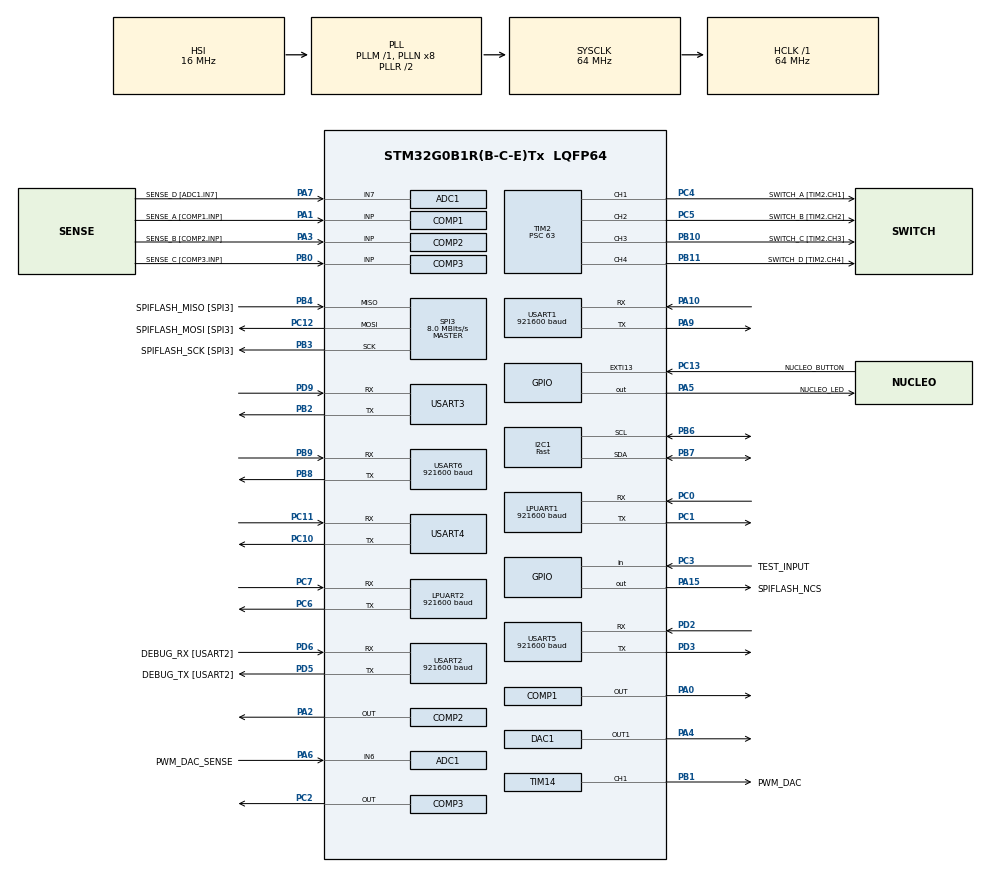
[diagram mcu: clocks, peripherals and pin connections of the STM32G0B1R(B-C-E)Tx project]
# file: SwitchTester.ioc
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ADC1.ContinuousConvMode=DISABLE
ADC1.DMAContinuousRequests=ENABLE
ADC1.EOCSelection=ADC_EOC_SEQ_CONV
ADC1.EnableAnalogWatchDog1=false
ADC1.NbrOfConversion=1
ADC1.NbrOfConversionFlag=0
ADC1.OversamplingMode=ENABLE
ADC1.Ratio=ADC_OVERSAMPLING_RATIO_4
ADC1.SamplingTimeCommon1=ADC_SAMPLETIME_12CYCLES_5
ADC1.SelectedChannel=ADC_CHANNEL_6|ADC_CHANNEL_7|ADC_CHANNEL_VREFINT|ADC_CHANNEL_VBAT
ADC1.Sequencer=NOT_FULLY_CONFIGURABLE
ADC1.master=1
COMP1.Hysteresis=COMP_HYSTERESIS_LOW
COMP1.TriggerMode=COMP_TRIGGERMODE_IT_RISING_FALLING
COMP2.Hysteresis=COMP_HYSTERESIS_LOW
COMP2.TriggerMode=COMP_TRIGGERMODE_IT_RISING_FALLING
COMP3.Hysteresis=COMP_HYSTERESIS_LOW
COMP3.TriggerMode=COMP_TRIGGERMODE_IT_RISING_FALLING
DAC1.DAC_Channel-DAC_OUT1_ExtAndInt=DAC_CHANNEL_1
DAC1.DAC_Channel-DAC_OUT2_Int=DAC_CHANNEL_2
Dma.ADC1.2.Direction=DMA_PERIPH_TO_MEMORY
Dma.ADC1.2.EventEnable=DISABLE
Dma.ADC1.2.Instance=DMA1_Channel3
Dma.ADC1.2.MemDataAlignment=DMA_MDATAALIGN_HALFWORD
Dma.ADC1.2.MemInc=DMA_MINC_ENABLE
Dma.ADC1.2.Mode=DMA_CIRCULAR
Dma.ADC1.2.PeriphDataAlignment=DMA_PDATAALIGN_HALFWORD
Dma.ADC1.2.PeriphInc=DMA_PINC_DISABLE
Dma.ADC1.2.Polarity=HAL_DMAMUX_REQ_GEN_RISING
Dma.ADC1.2.Priority=DMA_PRIORITY_LOW
Dma.ADC1.2.RequestNumber=1
Dma.ADC1.2.SignalID=NONE
Dma.ADC1.2.SyncEnable=DISABLE
Dma.ADC1.2.SyncPolarity=HAL_DMAMUX_SYNC_NO_EVENT
Dma.ADC1.2.SyncRequestNumber=1
Dma.ADC1.2.SyncSignalID=NONE
Dma.Request0=SPI3_RX
Dma.Request1=SPI3_TX
Dma.Request2=ADC1
Dma.SPI3_RX.0.Direction=DMA_PERIPH_TO_MEMORY
Dma.SPI3_RX.0.EventEnable=DISABLE
Dma.SPI3_RX.0.Instance=DMA1_Channel1
Dma.SPI3_RX.0.MemDataAlignment=DMA_MDATAALIGN_BYTE
Dma.SPI3_RX.0.MemInc=DMA_MINC_ENABLE
Dma.SPI3_RX.0.Mode=DMA_NORMAL
Dma.SPI3_RX.0.PeriphDataAlignment=DMA_PDATAALIGN_BYTE
Dma.SPI3_RX.0.PeriphInc=DMA_PINC_DISABLE
Dma.SPI3_RX.0.Polarity=HAL_DMAMUX_REQ_GEN_RISING
Dma.SPI3_RX.0.Priority=DMA_PRIORITY_LOW
Dma.SPI3_RX.0.RequestNumber=1
Dma.SPI3_RX.0.SignalID=NONE
Dma.SPI3_RX.0.SyncEnable=DISABLE
Dma.SPI3_RX.0.SyncPolarity=HAL_DMAMUX_SYNC_NO_EVENT
Dma.SPI3_RX.0.SyncRequestNumber=1
Dma.SPI3_RX.0.SyncSignalID=NONE
Dma.SPI3_TX.1.Direction=DMA_MEMORY_TO_PERIPH
Dma.SPI3_TX.1.EventEnable=DISABLE
Dma.SPI3_TX.1.Instance=DMA1_Channel2
Dma.SPI3_TX.1.MemDataAlignment=DMA_MDATAALIGN_BYTE
Dma.SPI3_TX.1.MemInc=DMA_MINC_ENABLE
Dma.SPI3_TX.1.Mode=DMA_NORMAL
Dma.SPI3_TX.1.PeriphDataAlignment=DMA_PDATAALIGN_BYTE
Dma.SPI3_TX.1.PeriphInc=DMA_PINC_DISABLE
Dma.SPI3_TX.1.Polarity=HAL_DMAMUX_REQ_GEN_RISING
Dma.SPI3_TX.1.Priority=DMA_PRIORITY_LOW
Dma.SPI3_TX.1.RequestNumber=1
Dma.SPI3_TX.1.SignalID=NONE
Dma.SPI3_TX.1.SyncEnable=DISABLE
Dma.SPI3_TX.1.SyncPolarity=HAL_DMAMUX_SYNC_NO_EVENT
Dma.SPI3_TX.1.SyncRequestNumber=1
Dma.SPI3_TX.1.SyncSignalID=NONE
I2C1.I2C_Speed_Mode=I2C_Fast
I2C1.Timing=0x00C12166
LPUART1.BaudRate=921600
LPUART1.FifoMode=UART_FIFOMODE_ENABLE
LPUART1.RXFIFOThreshold=UART_RXFIFO_THRESHOLD_1_2
LPUART1.TXFIFOThreshold=UART_TXFIFO_THRESHOLD_1_2
LPUART1.WordLength=UART_WORDLENGTH_8B
LPUART2.BaudRate=921600
LPUART2.FifoMode=UART_FIFOMODE_ENABLE
LPUART2.RXFIFOThreshold=UART_RXFIFO_THRESHOLD_1_2
LPUART2.TXFIFOThreshold=UART_TXFIFO_THRESHOLD_1_2
LPUART2.WordLength=UART_WORDLENGTH_8B
Mcu.Family=STM32G0
Mcu.Name=STM32G0B1R(B-C-E)Tx
Mcu.Package=LQFP64
NVIC.ADC1_COMP_IRQn=true\:1\:0\:true\:false\:true\:false\:true\:true
NVIC.DMA1_Channel1_IRQn=true\:0\:0\:false\:false\:true\:false\:true\:true
NVIC.DMA1_Channel2_3_IRQn=true\:0\:0\:false\:false\:true\:false\:true\:true
NVIC.EXTI4_15_IRQn=true\:3\:0\:true\:false\:true\:true\:true\:true
NVIC.RTC_TAMP_IRQn=true\:3\:0\:true\:false\:true\:true\:true\:true
NVIC.TIM17_FDCAN_IT1_IRQn=true\:3\:0\:true\:false\:true\:true\:true\:true
NVIC.TIM2_IRQn=true\:0\:0\:false\:false\:true\:true\:true\:true
NVIC.USART1_IRQn=true\:2\:0\:true\:false\:true\:true\:true\:true
NVIC.USART2_LPUART2_IRQn=true\:2\:0\:true\:false\:true\:true\:true\:true
NVIC.USART3_4_5_6_LPUART1_IRQn=true\:2\:0\:true\:false\:true\:true\:true\:true
PA0.Mode=ExternalOutput
PA0.Signal=COMP1_OUT
PA1.GPIO_Label=SENSE_A [COMP1.INP]
PA1.Mode=INP
PA1.Signal=COMP1_INP
PA10.Mode=Asynchronous
PA10.Signal=USART1_RX
PA13.GPIO_Label=SWDIO
PA13.Mode=Serial_Wire
PA13.Signal=SYS_SWDIO
PA14-BOOT0.GPIO_Label=SWCLK
PA14-BOOT0.Mode=Serial_Wire
PA14-BOOT0.Signal=SYS_SWCLK
PA15.GPIO_Label=SPIFLASH_NCS
PA15.PinState=GPIO_PIN_SET
PA15.Signal=GPIO_Output
PA2.Mode=ExternalOutput
PA2.Signal=COMP2_OUT
PA3.GPIO_Label=SENSE_B [COMP2.INP]
PA3.Mode=INP
PA3.Signal=COMP2_INP
PA4.Signal=COMP_DAC11_group
PA5.GPIO_Label=NUCLEO_LED
PA5.Signal=GPIO_Output
PA6.GPIO_Label=PWM_DAC_SENSE
PA6.Mode=IN6
PA6.Signal=ADC1_IN6
PA7.GPIO_Label=SENSE_D [ADC1.IN7]
PA7.Mode=IN7
PA7.Signal=ADC1_IN7
PA9.Mode=Asynchronous
PA9.Signal=USART1_TX
PB0.GPIO_Label=SENSE_C [COMP3.INP]
PB0.Mode=INP
PB0.Signal=COMP3_INP
PB1.GPIO_Label=PWM_DAC
PB1.Signal=S_TIM14_CH1
PB10.GPIO_Label=SWITCH_C [TIM2.CH3]
PB10.Signal=S_TIM2_CH3
PB11.GPIO_Label=SWITCH_D [TIM2.CH4]
PB11.Signal=S_TIM2_CH4
PB2.Mode=Asynchronous
PB2.Signal=USART3_TX
PB3.GPIO_Label=SPIFLASH_SCK [SPI3]
PB3.Mode=Full_Duplex_Master
PB3.Signal=SPI3_SCK
PB4.GPIO_Label=SPIFLASH_MISO [SPI3]
PB4.Mode=Full_Duplex_Master
PB4.Signal=SPI3_MISO
PB6.Mode=I2C
PB6.Signal=I2C1_SCL
PB7.Mode=I2C
PB7.Signal=I2C1_SDA
PB8.Mode=Asynchronous
PB8.Signal=USART6_TX
PB9.Mode=Asynchronous
PB9.Signal=USART6_RX
PC0.Mode=Asynchronous
PC0.Signal=LPUART1_RX
PC1.Mode=Asynchronous
PC1.Signal=LPUART1_TX
PC10.Mode=Asynchronous
PC10.Signal=USART4_TX
PC11.Mode=Asynchronous
PC11.Signal=USART4_RX
PC12.GPIO_Label=SPIFLASH_MOSI [SPI3]
PC12.Mode=Full_Duplex_Master
PC12.Signal=SPI3_MOSI
PC13.GPIO_Label=NUCLEO_BUTTON
PC13.GPIO_ModeDefaultEXTI=GPIO_MODE_IT_FALLING
PC13.Signal=GPXTI13
PC14-OSC32_IN\ (PC14).GPIO_Label=RTC_OSC32_IN
PC14-OSC32_IN\ (PC14).Mode=LSE-External-Oscillator
PC14-OSC32_IN\ (PC14).Signal=RCC_OSC32_IN
PC15-OSC32_OUT\ (PC15).GPIO_Label=RTC_OSC32_OUT
PC15-OSC32_OUT\ (PC15).Mode=LSE-External-Oscillator
PC15-OSC32_OUT\ (PC15).Signal=RCC_OSC32_OUT
PC2.Mode=ExternalOutput
PC2.Signal=COMP3_OUT
PC3.GPIO_Label=TEST_INPUT
PC3.GPIO_PuPd=GPIO_PULLUP
PC3.Signal=GPIO_Input
PC4.GPIO_Label=SWITCH_A [TIM2.CH1]
PC4.Signal=S_TIM2_CH1_ETR
PC5.GPIO_Label=SWITCH_B [TIM2.CH2]
PC5.Signal=S_TIM2_CH2
PC6.Mode=Asynchronous
PC6.Signal=LPUART2_TX
PC7.Mode=Asynchronous
PC7.Signal=LPUART2_RX
PD2.Mode=Asynchronous
PD2.Signal=USART5_RX
PD3.Mode=Asynchronous
PD3.Signal=USART5_TX
PD5.GPIO_Label=DEBUG_TX [USART2]
PD5.Mode=Asynchronous
PD5.Signal=USART2_TX
PD6.GPIO_Label=DEBUG_RX [USART2]
PD6.Mode=Asynchronous
PD6.Signal=USART2_RX
PD9.Mode=Asynchronous
PD9.Signal=USART3_RX
ProjectManager.HeapSize=0x400
ProjectManager.StackSize=0x400
ProjectManager.TargetToolchain=STM32CubeIDE
RCC.ADCFreq_Value=64000000
RCC.AHBFreq_Value=64000000
RCC.CortexFreq_Value=64000000
RCC.EXTERNAL_CLOCK_VALUE=12288000
RCC.HCLKFreq_Value=64000000
RCC.HSE_VALUE=8000000
RCC.HSI48_VALUE=48000000
RCC.HSI_VALUE=16000000
RCC.SYSCLKFreq_VALUE=64000000
RCC.SYSCLKSource=RCC_SYSCLKSOURCE_PLLCLK
RCC.USBFreq_Value=48000000
RCC.VCOOutputFreq_Value=128000000
RTC.SynchPrediv=249
SH.COMP_DAC11_group.0=DAC1_OUT1,DAC_OUT1_ExtAndInt
SH.S_TIM14_CH1.0=TIM14_CH1,PWM Generation1 CH1
SH.S_TIM2_CH1_ETR.0=TIM2_CH1,Output Compare1 CH1
SH.S_TIM2_CH2.0=TIM2_CH2,Output Compare2 CH2
SH.S_TIM2_CH3.0=TIM2_CH3,Output Compare3 CH3
SH.S_TIM2_CH4.0=TIM2_CH4,Output Compare4 CH4
SPI3.BaudRatePrescaler=SPI_BAUDRATEPRESCALER_8
SPI3.CalculateBaudRate=8.0 MBits/s
SPI3.DataSize=SPI_DATASIZE_8BIT
SPI3.Direction=SPI_DIRECTION_2LINES
SPI3.Mode=SPI_MODE_MASTER
SPI3.VirtualType=VM_MASTER
TIM1.Channel-Input_Capture1_from_TI1_REMAP_TIM1=TIM_CHANNEL_1
TIM1.Channel-Input_Capture2_from_TI2_Remap_TIM1=TIM_CHANNEL_2
TIM1.Channel-Input_Capture3_from_TI3_Remap_TIM1=TIM_CHANNEL_3
TIM1.ICPolarity_CH1=TIM_INPUTCHANNELPOLARITY_BOTHEDGE
TIM1.ICPolarity_CH2-Input_Capture2_from_TI2_Remap_TIM1=TIM_INPUTCHANNELPOLARITY_BOTHEDGE
TIM1.ICPolarity_CH2-Input_Capture3_from_TI3_Remap_TIM1=TIM_INPUTCHANNELPOLARITY_BOTHEDGE
TIM14.Channel=TIM_CHANNEL_1
TIM14.Period=1023
TIM14.Prescaler=0
TIM17.Period=999
TIM17.Prescaler=63
TIM2.Channel-Output\ Compare1\ CH1=TIM_CHANNEL_1
TIM2.Channel-Output\ Compare2\ CH2=TIM_CHANNEL_2
TIM2.Channel-Output\ Compare3\ CH3=TIM_CHANNEL_3
TIM2.Channel-Output\ Compare4\ CH4=TIM_CHANNEL_4
TIM2.OCMode_1=TIM_OCMODE_FORCED_INACTIVE
TIM2.OCMode_2=TIM_OCMODE_FORCED_INACTIVE
TIM2.OCMode_3=TIM_OCMODE_FORCED_INACTIVE
TIM2.OCMode_4=TIM_OCMODE_FORCED_INACTIVE
TIM2.Prescaler=63
TIM6.Period=99
TIM6.Prescaler=63
TIM7.Prescaler=63
USART1.BaudRate=921600
USART1.FIFOMode=FIFOMODE_ENABLE
USART1.RXFIFOThreshold=RXFIFO_THRESHOLD_HALFFULL
USART1.TXFIFOThreshold=TXFIFO_THRESHOLD_HALFFULL
USART1.VirtualMode-Asynchronous=VM_ASYNC
USART2.BaudRate=921600
USART2.FIFOMode=FIFOMODE_ENABLE
USART2.RXFIFOThreshold=RXFIFO_THRESHOLD_1QUARTERFULL
USART2.TXFIFOThreshold=TXFIFO_THRESHOLD_1QUARTERFULL
USART2.VirtualMode-Asynchronous=VM_ASYNC
USART3.FIFOMode=FIFOMODE_ENABLE
USART3.RXFIFOThreshold=RXFIFO_THRESHOLD_HALFFULL
USART3.TXFIFOThreshold=TXFIFO_THRESHOLD_HALFFULL
USART3.VirtualMode-Asynchronous=VM_ASYNC
USART4.VirtualMode-Asynchronous=VM_ASYNC
USART5.BaudRate=921600
USART5.VirtualMode-Asynchronous=VM_ASYNC
USART6.BaudRate=921600
USART6.VirtualMode-Asynchronous=VM_ASYNC
VP_ADC1_Vbat_Input.Mode=IN-Vbat
VP_ADC1_Vref_Input.Mode=IN-Vrefint
VP_COMP1_VS_DACOUT1.Mode=INM_DACOUT1
VP_COMP2_VS_DACOUT2.Mode=INM_DACOUT2
VP_COMP3_VS_DACOUT2.Mode=INM_DACOUT2
VP_CRC_VS_CRC.Mode=CRC_Activate
VP_DAC1_VS_DACI2.Mode=DAC_OUT2_Int
VP_RTC_VS_RTC_Activate.Mode=RTC_Enabled
VP_RTC_VS_RTC_WakeUp_intern.Mode=WakeUp
VP_SYS_VS_DBSignals.Mode=DisableDeadBatterySignals
VP_TIM14_VS_ClockSourceINT.Mode=Enable_Timer
VP_TIM17_VS_ClockSourceINT.Mode=Enable_Timer
VP_TIM1_VS_ClockSourceINT.Mode=Internal
VP_TIM1_VS_NoInput1.Mode=Input_Capture1_from_TI1_REMAP_TIM1
VP_TIM1_VS_NoInput2.Mode=Input_Capture2_from_TI2_Remap_TIM1
VP_TIM1_VS_NoInput3.Mode=Input_Capture3_from_TI3_Remap_TIM1
VP_TIM2_VS_ClockSourceINT.Mode=Internal
VP_TIM6_VS_ClockSourceINT.Mode=Enable_Timer
VP_TIM7_VS_ClockSourceINT.Mode=Enable_Timer
board=NUCLEO-G0B1RE

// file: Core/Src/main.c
/* USER CODE BEGIN Header */
/**
  ******************************************************************************
  * @file           : main.c
  * @brief          : Main program body
  ******************************************************************************
  * @attention
  *
  * Copyright (c) 2025 STMicroelectronics.
  * All rights reserved.
  *
  * This software is licensed under terms that can be found in the LICENSE file
  * in the root directory of this software component.
  * If no LICENSE file comes with this software, it is provided AS-IS.
  *
  ******************************************************************************
  */
/* USER CODE END Header */
#include "main.h"
#include "adc.h"
#include "comp.h"
#include "crc.h"
#include "dac.h"
#include "dma.h"
#include "i2c.h"
#include "usart.h"
#include "rtc.h"
#include "spi.h"
#include "tim.h"
#include "gpio.h"

/* USER CODE BEGIN Includes */

#include "device_config.h"
#include "stdio_retarget.h"
#include "utils.h"

/* USER CODE END Includes */

void SystemClock_Config(void);

int main(void)
{

  /* MCU Configuration--------------------------------------------------------*/

  /* Reset of all peripherals, Initializes the Flash interface and the Systick. */
  HAL_Init();

  /* Configure the system clock */
  SystemClock_Config();

  /* Initialize all configured peripherals */
  MX_GPIO_Init();
  MX_DMA_Init();
  MX_USART2_UART_Init();
  MX_TIM7_Init();
  MX_ADC1_Init();
  MX_TIM2_Init();
  MX_COMP1_Init();
  MX_COMP2_Init();
  MX_COMP3_Init();
  MX_DAC1_Init();
  MX_RTC_Init();
  MX_TIM14_Init();
  MX_LPUART1_UART_Init();
  MX_LPUART2_UART_Init();
  MX_USART1_UART_Init();
  MX_USART3_UART_Init();
  MX_USART4_UART_Init();
  MX_USART5_UART_Init();
  MX_USART6_UART_Init();
  MX_SPI3_Init();
  MX_CRC_Init();
  MX_I2C1_Init();
  MX_TIM6_Init();
  MX_TIM1_Init();
  MX_TIM17_Init();
  /* USER CODE BEGIN 2 */

  v_stdio_retarget(&DEBUG_UART_HANDLE);
  x_get_reset_source();

  /* USER CODE END 2 */

  /* Infinite loop */
  /* USER CODE BEGIN WHILE */
  extern void app_main(void);
  app_main();   // This function never returns
    /* USER CODE END WHILE */

}

void SystemClock_Config(void)
{
  RCC_OscInitTypeDef RCC_OscInitStruct = {0};
  RCC_ClkInitTypeDef RCC_ClkInitStruct = {0};

  /** Configure the main internal regulator output voltage
  */
  HAL_PWREx_ControlVoltageScaling(PWR_REGULATOR_VOLTAGE_SCALE1);

  /** Initializes the RCC Oscillators according to the specified parameters
  * in the RCC_OscInitTypeDef structure.
  */
  RCC_OscInitStruct.OscillatorType = RCC_OSCILLATORTYPE_HSI|RCC_OSCILLATORTYPE_LSI;
  RCC_OscInitStruct.HSIState = RCC_HSI_ON;
  RCC_OscInitStruct.HSIDiv = RCC_HSI_DIV1;
  RCC_OscInitStruct.HSICalibrationValue = RCC_HSICALIBRATION_DEFAULT;
  RCC_OscInitStruct.LSIState = RCC_LSI_ON;
  RCC_OscInitStruct.PLL.PLLState = RCC_PLL_ON;
  RCC_OscInitStruct.PLL.PLLSource = RCC_PLLSOURCE_HSI;
  RCC_OscInitStruct.PLL.PLLM = RCC_PLLM_DIV1;
  RCC_OscInitStruct.PLL.PLLN = 8;
  RCC_OscInitStruct.PLL.PLLP = RCC_PLLP_DIV2;
  RCC_OscInitStruct.PLL.PLLQ = RCC_PLLQ_DIV2;
  RCC_OscInitStruct.PLL.PLLR = RCC_PLLR_DIV2;
  if (HAL_RCC_OscConfig(&RCC_OscInitStruct) != HAL_OK)
  {
    Error_Handler();
  }

  /** Initializes the CPU, AHB and APB buses clocks
  */
  RCC_ClkInitStruct.ClockType = RCC_CLOCKTYPE_HCLK|RCC_CLOCKTYPE_SYSCLK
                              |RCC_CLOCKTYPE_PCLK1;
  RCC_ClkInitStruct.SYSCLKSource = RCC_SYSCLKSOURCE_PLLCLK;
  RCC_ClkInitStruct.AHBCLKDivider = RCC_SYSCLK_DIV1;
  RCC_ClkInitStruct.APB1CLKDivider = RCC_HCLK_DIV1;

  if (HAL_RCC_ClockConfig(&RCC_ClkInitStruct, FLASH_LATENCY_2) != HAL_OK)
  {
    Error_Handler();
  }
}

void Error_Handler(void)
{
  __disable_irq();
  while (1)
  {
  }
}
